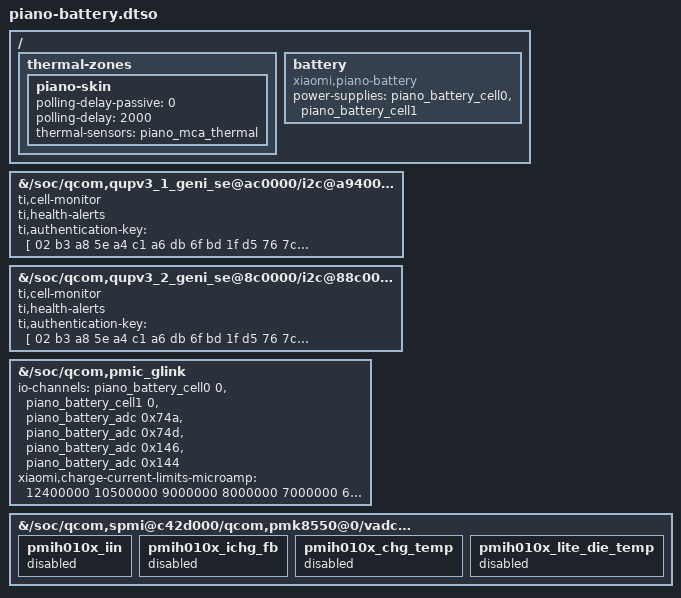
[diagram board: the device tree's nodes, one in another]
// SPDX-License-Identifier: GPL-2.0-only OR BSD-2-Clause
/dts-v1/;
/plugin/;

/* The parallel cells are measurement components of one physical battery. */
/ {
	fragment@0 {
		target-path = "/soc/qcom,qupv3_1_geni_se@ac0000/i2c@a94000/bq27z561_master@55";
		piano_battery_cell0: __overlay__ {
			#io-channel-cells = <1>;
			ti,cell-monitor;
			ti,health-alerts;
			ti,authentication-key = [
				02 b3 a8 5e a4 c1 a6 db 6f bd 1f d5 76 7c 1a 42
				31 4f 37 ba 7c 94 60 c9 ed 79 a1 2b b2 b5 d9 9c
			];
		};
	};

	fragment@1 {
		target-path = "/soc/qcom,qupv3_2_geni_se@8c0000/i2c@88c000/bq27z561_slave@55";
		piano_battery_cell1: __overlay__ {
			#io-channel-cells = <1>;
			ti,cell-monitor;
			ti,health-alerts;
			ti,authentication-key = [
				02 b3 a8 5e a4 c1 a6 db 6f bd 1f d5 76 7c 1a 42
				31 4f 37 ba 7c 94 60 c9 ed 79 a1 2b b2 b5 d9 9c
			];
		};
	};

	fragment@2 {
		target-path = "/";
		__overlay__ {
			thermal-zones {
				piano-skin {
					polling-delay-passive = <0>;
					polling-delay = <2000>;
					thermal-sensors = <&piano_mca_thermal>;
				};
			};

			battery {
				compatible = "xiaomi,piano-battery";
				power-supplies = <&piano_battery_cell0 &piano_battery_cell1>;
			};
		};
	};

	fragment@3 {
		target-path = "/soc/qcom,pmic_glink";
		piano_mca_thermal: __overlay__ {
			#thermal-sensor-cells = <0>;
			io-channels = <&piano_battery_cell0 0>, <&piano_battery_cell1 0>,
				      <&piano_battery_adc 0x74a>, <&piano_battery_adc 0x74d>,
				      <&piano_battery_adc 0x146>, <&piano_battery_adc 0x144>;
			io-channel-names = "battery0", "battery1", "quiet-therm",
					   "charger-therm", "wifi-therm", "cpu-therm";
			#cooling-cells = <2>;
			/* Both modes share the factory current levels and stop state. */
			xiaomi,charge-current-limits-microamp = <
				12400000 10500000 9000000 8000000 7000000 6200000
				5500000 5000000 4400000
				3600000 3000000 2500000 2000000 1500000 1000000
				700000 0
			>;
		};
	};

	fragment@4 {
		target-path = "/soc/qcom,spmi@c42d000/qcom,pmk8550@0/vadc@9000";
		piano_battery_adc: __overlay__ {
			/* These charger-specific channels have no native scaling support. */
			pmih010x_iin {
				status = "disabled";
			};
			pmih010x_ichg_fb {
				status = "disabled";
			};
			pmih010x_chg_temp {
				status = "disabled";
			};
			pmih010x_lite_die_temp {
				status = "disabled";
			};
		};
	};
};
